# A31G21x register map
Vendor: ABOV Semiconductor Co., Ltd.; Series: A31G21x; File version: 1.0
CPU: CM0PLUS r0p1, little endian, no MPU, no FPU, VTOR, 2 interrupt priority bits
Registers are 32-bit, read-write, reset 0x0 unless marked. A register's access mark holds for its fields unless they carry their own. Offsets are from the block's base; [hi:lo] are bit positions.

## I2C0
Base 0x40004800
Same registers: I2C1 0x40004900
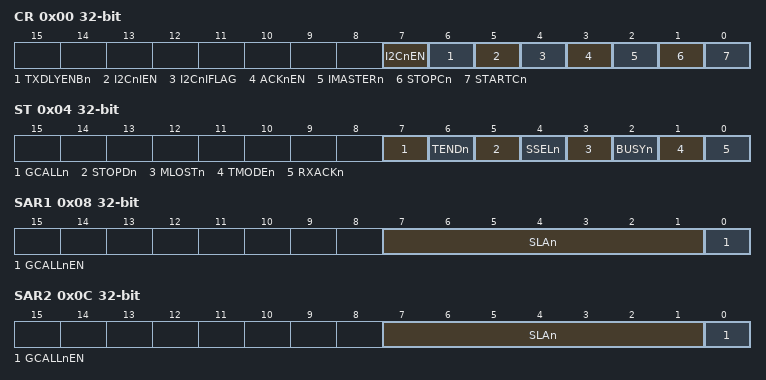
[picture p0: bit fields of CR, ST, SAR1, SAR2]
0x00 CR — I2Cn Control Register
  [7] I2CnEN — Activate I2Cn Block by supplying
  [6] TXDLYENBn — I2CnSDHR Register Control bit
  [5] I2CnIEN — I2Cn Interrupt Enable bit
  [4] I2CnIFLAG — I2Cn Interrupt Flag bit. This bit is cleared when write any values in the I2CnST register.
  [3] ACKnEN — Controls ACK signal generation at ninth SCL period. Notes) ACK signal is output (SDA = 0) for the following 3 cases. Where x = 0 and 1. 1. When received address packet equals to SLAx[6:0] bits in I2CnSARx register. 2. When received address packet equals to value 0x00 with GCALLn enabled. 3. When I2Cn operates as a receiver (master or slave)
  [2] IMASTERn ro — Represent Operation Mode of I2Cn
  [1] STOPCn — STOP Condition Generation When I2Cn is master.
  [0] STARTCn — START Condition Generation When I2Cn is master.
0x04 ST — I2Cn Status Register
  [7] GCALLn — This bit has different meaning depending on whether I2C is master or slave. When I2C is a master, this bit represents whether it received AACK (address ACK) from slave.
  [6] TENDn — This bit is set when 1-byte of data is transferred completely.
  [5] STOPDn — This bit is set when a STOP condition is detected.
  [4] SSELn — This bit is set when I2C is addressed by other master.
  [3] MLOSTn — This bit represents the result of bus arbitration in master mode.
  [2] BUSYn — This bit reflects bus status.
  [1] TMODEn ro — This bit is used to indicate whether I2C is transmitter or receiver.
  [0] RXACKn — This bit shows the state of ACK signal.
0x08 SAR1 — I2Cn Slave Address Register 1
  [7:1] SLAn — These bits configure the slave address 0 in slave mode.
  [0] GCALLnEN — This bit decides whether I2Cn allows general call address 0 or not in I2Cn slave mode.
0x0C SAR2 — I2Cn Slave Address Register 2
  [7:1] SLAn — These bits configure the slave address 1 in slave mode.
  [0] GCALLnEN — This bit decides whether I2Cn allows general call address 1 or not in I2Cn slave mode.
0x10 DR — I2Cn Data Register
  [7:0] DATA — The I2CnDR Transmit buffer and Receive buffer share the same I/O address with this DATA register. The Transmit Data Buffer is the destination for data written to the I2CnDR register. Reading the I2CnDR register returns the contents of the Receive Buffer.
0x14 SDHR reset 0x1 — I2Cn SDA Hold Time Register
  [11:0] HLDT — This register is used to control SDA output timing from the falling edge of SCL. Note that SDA is changed after tPCLK X (I2CnSDHR+2). In master mode, load half the value of I2CnSCLR to this register to make SDA change in the middle of SCL. In slave mode, configure this register regarding the frequency of SCL from master. The SDA is changed after tPCLK X (I2CnSDHR+2) in master mode. So, to insure operation in slave mode, the value tPCLK X (I2CnSDHR + 2) must be smaller than the period of SCL.
0x18 SCLR reset 0x3F — I2Cn SCL Low Period Register
  [11:0] SCLL — This register defines the low period of SCL in master mode. The base clock is PCLK and the period is calculated by the formula: tPCLK X (4 X I2CnSCLR + 2) where tPCLK is the period of PCLK.
0x1C SCHR reset 0x3F — I2Cn SCL High Period Register
  [11:0] SCLH — This register defines the high period of SCL in master mode. The base clock is PCLK and the period is calculated by the formula: tPCLK X (4 X I2CnSCHR + 2) where tPCLK is the period of PCLK.

## SPI20 — Serial Peripheral Interface Bus
Base 0x40004C00
Same registers: SPI21 0x40004D00
0x00 TDR wo — SPI2 n Transmit Data Register
  [16:0] TDR — Transmit Data Bit
0x00 RDR ro — SPI n Received Data Register
  [16:0] RDR — Received Data Bit
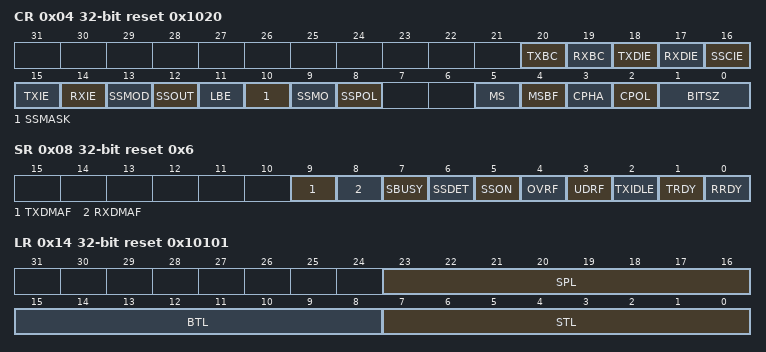
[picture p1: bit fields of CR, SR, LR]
0x04 CR reset 0x1020 — SPI Control Register
  [20] TXBC — Tx Buffer Clear Bit
  [19] RXBC — Rx Buffer Clear Bit
  [18] TXDIE — DMA Tx Complete Interrupt Enable Bit
  [17] RXDIE — DMA Rx Complete Interrupt Enable Bit
  [16] SSCIE — SS Edge Changed Interrupt Enable Bit
  [15] TXIE — Transmit Interrupt Enable Bit
  [14] RXIE — Received Interrupt Enable Bit
  [13] SSMOD — SS Auto/Manual Output Selection Bit in Master Mode
  [12] SSOUT — SS Output Signal Control Bit
  [11] LBE — Loop-back Mode Selection Bit in Master Mode
  [10] SSMASK — SS Signal Masking in Slave Mode
  [9] SSMO — SS Output Signal Selection Bit
  [8] SSPOL — SS Signal Polarity Selection Bit
  [5] MS — Master/Slave Selection Bit
  [4] MSBF — MSB/LSB Transmit Advance Selection Bit
  [3] CPHA — SPI Clock Phase Bit
  [2] CPOL — SPI Clock Polarity Bit
  [1:0] BITSZ — Transmit/Receive Bit Size Selection Bit
    0=8_BIT (Size is 8 bit); 1=9_BIT (Size is 9 bit); 2=16_BIT (Size is 16 bit); 3=17_BIT (Size is 17 bit)
0x08 SR reset 0x6 — SPI n Status Register
  [9] TXDMAF — DMA Transmit Operation Complete Flag
  [8] RXDMAF — DMA Received Operation Complete Flag
  [7] SBUSY ro — Transmit/Received Operating Flag
  [6] SSDET — SS Signal Rising or Falling Edge Detected Flag
  [5] SSON — SS Signal Status Flag
  [4] OVRF — Received Overrun Error Flag
  [3] UDRF — Transmit Underrun Error Flag
  [2] TXIDLE ro — Transmit Operating Flag
  [1] TRDY ro — Transmit Buffer Empty Flag
  [0] RRDY ro — Received Buffer Empty Flag
0x0C BR reset 0xFF — SPI n Baud Rate Register
  [15:0] BR — Baud Rate Setting Bit
0x10 EN — SPI n Enable Register
  [0] ENABLE — SPI Enable Bit
0x14 LR reset 0x10101 — SPI n Delay Length Register
  [23:16] SPL — SPI STOP Length Value Bit
  [15:8] BTL — SPI Burst Length Value Bit
  [7:0] STL — SPI Start Length Value Bit
